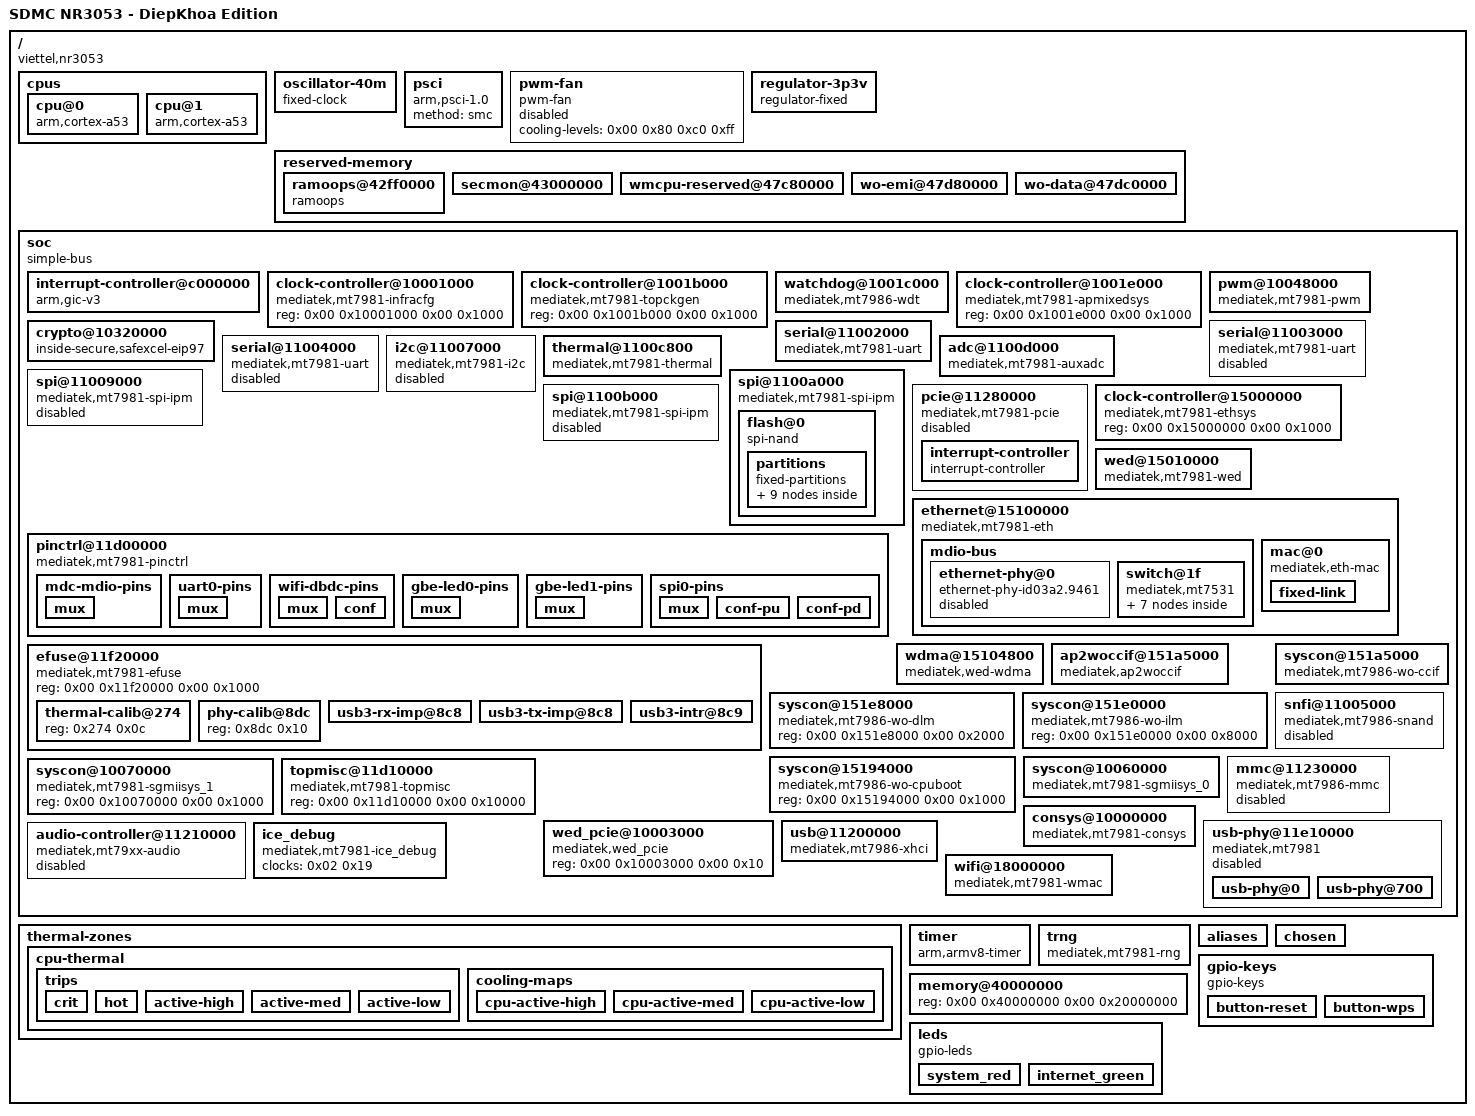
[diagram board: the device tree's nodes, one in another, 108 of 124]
/dts-v1/;

/ {
	compatible = "viettel,nr3053", "sdmc,nr3053", "mediatek,mt7981";
	interrupt-parent = <0x01>;
	#address-cells = <0x02>;
	#size-cells = <0x02>;
	model = "SDMC NR3053 - DiepKhoa Edition";

	cpus {
		#address-cells = <0x01>;
		#size-cells = <0x00>;

		cpu@0 {
			compatible = "arm,cortex-a53";
			reg = <0x00>;
			device_type = "cpu";
			enable-method = "psci";
		};

		cpu@1 {
			compatible = "arm,cortex-a53";
			reg = <0x01>;
			device_type = "cpu";
			enable-method = "psci";
		};
	};

	oscillator-40m {
		compatible = "fixed-clock";
		clock-frequency = <0x2625a00>;
		clock-output-names = "clkxtal";
		#clock-cells = <0x00>;
	};

	psci {
		compatible = "arm,psci-1.0";
		method = "smc";
	};

	pwm-fan {
		compatible = "pwm-fan";
		cooling-levels = <0x00 0x80 0xc0 0xff>;
		#cooling-cells = <0x02>;
		status = "disabled";
		phandle = <0x22>;
	};

	regulator-3p3v {
		compatible = "regulator-fixed";
		regulator-name = "fixed-3.3V";
		regulator-min-microvolt = <0x325aa0>;
		regulator-max-microvolt = <0x325aa0>;
		regulator-boot-on;
		regulator-always-on;
		phandle = <0x1d>;
	};

	reserved-memory {
		#address-cells = <0x02>;
		#size-cells = <0x02>;
		ranges;

		ramoops@42ff0000 {
			compatible = "ramoops";
			reg = <0x00 0x42ff0000 0x00 0x10000>;
			record-size = <0x1000>;
		};

		secmon@43000000 {
			reg = <0x00 0x43000000 0x00 0x30000>;
			no-map;
			phandle = <0x27>;
		};

		wmcpu-reserved@47c80000 {
			reg = <0x00 0x47c80000 0x00 0x100000>;
			no-map;
			phandle = <0x1b>;
		};

		wo-emi@47d80000 {
			reg = <0x00 0x47d80000 0x00 0x40000>;
			no-map;
			phandle = <0x0b>;
		};

		wo-data@47dc0000 {
			reg = <0x00 0x47dc0000 0x00 0x240000>;
			no-map;
			phandle = <0x0c>;
		};
	};

	soc {
		compatible = "simple-bus";
		ranges;
		#address-cells = <0x02>;
		#size-cells = <0x02>;

		interrupt-controller@c000000 {
			compatible = "arm,gic-v3";
			reg = <0x00 0xc000000 0x00 0x40000 0x00 0xc080000 0x00 0x200000>;
			interrupt-parent = <0x01>;
			interrupts = <0x01 0x09 0x04>;
			interrupt-controller;
			#interrupt-cells = <0x03>;
			phandle = <0x01>;
		};

		clock-controller@10001000 {
			compatible = "mediatek,mt7981-infracfg", "syscon";
			reg = <0x00 0x10001000 0x00 0x1000>;
			#clock-cells = <0x01>;
			phandle = <0x02>;
		};

		clock-controller@1001b000 {
			compatible = "mediatek,mt7981-topckgen", "syscon";
			reg = <0x00 0x1001b000 0x00 0x1000>;
			#clock-cells = <0x01>;
			phandle = <0x03>;
		};

		watchdog@1001c000 {
			compatible = "mediatek,mt7986-wdt";
			reg = <0x00 0x1001c000 0x00 0x1000>;
			interrupts = <0x00 0x6e 0x04>;
			#reset-cells = <0x01>;
			status = "okay";
			phandle = <0x1f>;
		};

		clock-controller@1001e000 {
			compatible = "mediatek,mt7981-apmixedsys", "syscon";
			reg = <0x00 0x1001e000 0x00 0x1000>;
			#clock-cells = <0x01>;
			phandle = <0x05>;
		};

		pwm@10048000 {
			compatible = "mediatek,mt7981-pwm";
			reg = <0x00 0x10048000 0x00 0x1000>;
			clocks = <0x02 0x0e 0x02 0x0d 0x02 0x0f 0x02 0x10 0x02 0x11>;
			clock-names = "top", "main", "pwm1", "pwm2", "pwm3";
			#pwm-cells = <0x02>;
			phandle = <0x28>;
		};

		crypto@10320000 {
			compatible = "inside-secure,safexcel-eip97";
			reg = <0x00 0x10320000 0x00 0x40000>;
			interrupts = <0x00 0x74 0x04 0x00 0x75 0x04 0x00 0x76 0x04 0x00 0x77 0x04>;
			interrupt-names = "ring0", "ring1", "ring2", "ring3";
			clocks = <0x03 0x42>;
			clock-names = "top_eip97_ck";
			assigned-clocks = <0x03 0x63>;
			assigned-clock-parents = <0x03 0x15>;
			phandle = <0x29>;
		};

		serial@11002000 {
			compatible = "mediatek,mt7981-uart", "mediatek,mt6577-uart";
			reg = <0x00 0x11002000 0x00 0x100>;
			interrupts = <0x00 0x7b 0x04>;
			interrupt-names = "uart", "wakeup";
			clocks = <0x02 0x01 0x02 0x1f>;
			clock-names = "baud", "bus";
			status = "okay";
			phandle = <0x2a>;
		};

		serial@11003000 {
			compatible = "mediatek,mt7981-uart", "mediatek,mt6577-uart";
			reg = <0x00 0x11003000 0x00 0x100>;
			interrupts = <0x00 0x7c 0x04>;
			interrupt-names = "uart", "wakeup";
			clocks = <0x02 0x02 0x02 0x20>;
			clock-names = "baud", "bus";
			status = "disabled";
			phandle = <0x2b>;
		};

		serial@11004000 {
			compatible = "mediatek,mt7981-uart", "mediatek,mt6577-uart";
			reg = <0x00 0x11004000 0x00 0x100>;
			interrupts = <0x00 0x7d 0x04>;
			interrupt-names = "uart", "wakeup";
			clocks = <0x02 0x03 0x02 0x21>;
			clock-names = "baud", "bus";
			status = "disabled";
			phandle = <0x2c>;
		};

		i2c@11007000 {
			compatible = "mediatek,mt7981-i2c";
			reg = <0x00 0x11007000 0x00 0x1000 0x00 0x10217080 0x00 0x80>;
			interrupts = <0x00 0x88 0x04>;
			clock-div = <0x01>;
			clocks = <0x02 0x1e 0x02 0x1a 0x02 0x33 0x02 0x34>;
			clock-names = "main", "dma", "arb", "pmic";
			#address-cells = <0x01>;
			#size-cells = <0x00>;
			status = "disabled";
			phandle = <0x2d>;
		};

		thermal@1100c800 {
			#thermal-sensor-cells = <0x01>;
			compatible = "mediatek,mt7981-thermal", "mediatek,mt7986-thermal";
			reg = <0x00 0x1100c800 0x00 0x800>;
			interrupts = <0x00 0x8a 0x04>;
			clocks = <0x02 0x1d 0x02 0x30>;
			clock-names = "therm", "auxadc";
			mediatek,auxadc = <0x04>;
			mediatek,apmixedsys = <0x05>;
			nvmem-cells = <0x06>;
			nvmem-cell-names = "calibration-data";
			phandle = <0x21>;
		};

		adc@1100d000 {
			compatible = "mediatek,mt7981-auxadc", "mediatek,mt7986-auxadc", "mediatek,mt7622-auxadc";
			reg = <0x00 0x1100d000 0x00 0x1000>;
			clocks = <0x02 0x30 0x02 0x31>;
			clock-names = "main", "32k";
			#io-channel-cells = <0x01>;
			phandle = <0x04>;
		};

		spi@11009000 {
			compatible = "mediatek,mt7981-spi-ipm", "mediatek,spi-ipm";
			reg = <0x00 0x11009000 0x00 0x1000>;
			interrupts = <0x00 0x8e 0x04>;
			clocks = <0x03 0x02 0x03 0x4e 0x02 0x22 0x02 0x23>;
			clock-names = "parent-clk", "sel-clk", "spi-clk", "hclk";
			#address-cells = <0x01>;
			#size-cells = <0x00>;
			status = "disabled";
			phandle = <0x2e>;
		};

		spi@1100a000 {
			compatible = "mediatek,mt7981-spi-ipm", "mediatek,spi-ipm";
			reg = <0x00 0x1100a000 0x00 0x1000>;
			interrupts = <0x00 0x8c 0x04>;
			clocks = <0x03 0x02 0x03 0x4e 0x02 0x27 0x02 0x29>;
			clock-names = "parent-clk", "sel-clk", "spi-clk", "hclk";
			#address-cells = <0x01>;
			#size-cells = <0x00>;
			status = "okay";
			pinctrl-names = "default";
			pinctrl-0 = <0x07>;
			phandle = <0x2f>;

			flash@0 {
				compatible = "spi-nand";
				reg = <0x00>;
				spi-max-frequency = <0x3197500>;
				spi-tx-bus-width = <0x04>;
				spi-rx-bus-width = <0x04>;
				mediatek,nmbm;
				mediatek,bmt-max-ratio = <0x01>;
				mediatek,bmt-max-reserved-blocks = <0x40>;
				phandle = <0x30>;

				partitions {
					compatible = "fixed-partitions";
					#address-cells = <0x01>;
					#size-cells = <0x01>;

					partition@0 {
						label = "bl2";
						reg = <0x00 0x100000>;
						read-only;
					};

					partition@100000 {
						label = "u-boot-env";
						reg = <0x100000 0x100000>;
					};

					partition@200000 {
						label = "Factory";
						reg = <0x200000 0x200000>;
						read-only;
						phandle = <0x20>;

						nvmem-layout {
							compatible = "fixed-layout";
							#address-cells = <0x01>;
							#size-cells = <0x01>;

							macaddr@4 {
								compatible = "mac-base";
								reg = <0x04 0x06>;
								#nvmem-cell-cells = <0x01>;
								phandle = <0x19>;
							};
						};
					};

					partition@400000 {
						label = "fip";
						reg = <0x400000 0x200000>;
						read-only;
					};

					partition@600000 {
						label = "ubi";
						reg = <0x600000 0xea00000>;
						compatible = "linux,ubi";

						volumes {
							ubi-volume-fit {
								volname = "fit";
								phandle = <0x26>;
							};
						};
					};
				};
			};
		};

		spi@1100b000 {
			compatible = "mediatek,mt7981-spi-ipm", "mediatek,spi-ipm";
			reg = <0x00 0x1100b000 0x00 0x1000>;
			interrupts = <0x00 0x8d 0x04>;
			clocks = <0x03 0x02 0x03 0x4e 0x02 0x28 0x02 0x2a>;
			clock-names = "parent-clk", "sel-clk", "spi-clk", "hclk";
			#address-cells = <0x01>;
			#size-cells = <0x00>;
			status = "disabled";
			phandle = <0x31>;
		};

		pcie@11280000 {
			compatible = "mediatek,mt7981-pcie", "mediatek,mt8192-pcie";
			device_type = "pci";
			reg = <0x00 0x11280000 0x00 0x4000>;
			reg-names = "pcie-mac";
			#address-cells = <0x03>;
			#size-cells = <0x02>;
			interrupts = <0x00 0xa8 0x04>;
			bus-range = <0x00 0xff>;
			ranges = <0x82000000 0x00 0x20000000 0x00 0x20000000 0x00 0x10000000>;
			status = "disabled";
			clocks = <0x02 0x39 0x02 0x3a 0x02 0x3b 0x02 0x3c>;
			phys = <0x08 0x02>;
			phy-names = "pcie-phy";
			#interrupt-cells = <0x01>;
			interrupt-map-mask = <0x00 0x00 0x00 0x07>;
			interrupt-map = <0x00 0x00 0x00 0x01 0x09 0x00 0x00 0x00 0x00 0x02 0x09 0x01 0x00 0x00 0x00 0x03 0x09 0x02 0x00 0x00 0x00 0x04 0x09 0x03>;
			phandle = <0x32>;

			interrupt-controller {
				interrupt-controller;
				#address-cells = <0x00>;
				#interrupt-cells = <0x01>;
				phandle = <0x09>;
			};
		};

		pinctrl@11d00000 {
			compatible = "mediatek,mt7981-pinctrl";
			reg = <0x00 0x11d00000 0x00 0x1000 0x00 0x11c00000 0x00 0x1000 0x00 0x11c10000 0x00 0x1000 0x00 0x11d20000 0x00 0x1000 0x00 0x11e00000 0x00 0x1000 0x00 0x11e20000 0x00 0x1000 0x00 0x11f00000 0x00 0x1000 0x00 0x11f10000 0x00 0x1000 0x00 0x1000b000 0x00 0x1000>;
			reg-names = "gpio", "iocfg_rt", "iocfg_rm", "iocfg_rb", "iocfg_lb", "iocfg_bl", "iocfg_tm", "iocfg_tl", "eint";
			interrupt-controller;
			interrupts = <0x00 0xe1 0x04>;
			interrupt-parent = <0x01>;
			gpio-ranges = <0x0a 0x00 0x00 0x38>;
			gpio-controller;
			#gpio-cells = <0x02>;
			#interrupt-cells = <0x02>;
			phandle = <0x0a>;

			mdc-mdio-pins {
				phandle = <0x33>;
				mux {
					function = "eth";
					groups = "smi_mdc_mdio";
				};
			};

			uart0-pins {
				phandle = <0x34>;
				mux {
					function = "uart";
					groups = "uart0";
				};
			};

			wifi-dbdc-pins {
				phandle = <0x1e>;
				mux {
					function = "eth";
					groups = "wf0_mode1";
				};
				conf {
					pins = "WF_HB1", "WF_HB2", "WF_HB3", "WF_HB4", "WF_HB0", "WF_HB0_B", "WF_HB5", "WF_HB6", "WF_HB7", "WF_HB8", "WF_HB9", "WF_HB10", "WF_TOP_CLK", "WF_TOP_DATA", "WF_XO_REQ", "WF_CBA_RESETB", "WF_DIG_RESETB";
					drive-strength = <0x04>;
				};
			};

			gbe-led0-pins {
				phandle = <0x17>;
				mux {
					function = "led";
					groups = "gbe_led0";
				};
			};

			gbe-led1-pins {
				phandle = <0x18>;
				mux {
					function = "led";
					groups = "gbe_led1";
				};
			};

			spi0-pins {
				phandle = <0x07>;
				mux {
					function = "spi";
					groups = "spi0", "spi0_wp_hold";
				};
				conf-pu {
					pins = "SPI0_CS", "SPI0_HOLD", "SPI0_WP";
					drive-strength = <0x08>;
					bias-pull-up = <0x67>;
				};
				conf-pd {
					pins = "SPI0_CLK", "SPI0_MOSI", "SPI0_MISO";
					drive-strength = <0x08>;
					bias-pull-down = <0x67>;
				};
			};
		};

		efuse@11f20000 {
			compatible = "mediatek,mt7981-efuse", "mediatek,efuse";
			reg = <0x00 0x11f20000 0x00 0x1000>;
			#address-cells = <0x01>;
			#size-cells = <0x01>;

			thermal-calib@274 {
				reg = <0x274 0x0c>;
				phandle = <0x06>;
			};

			phy-calib@8dc {
				reg = <0x8dc 0x10>;
				phandle = <0x16>;
			};

			usb3-rx-imp@8c8 {
				reg = <0x8c8 0x01>;
				bits = <0x00 0x05>;
				phandle = <0x35>;
			};

			usb3-tx-imp@8c8 {
				reg = <0x8c8 0x02>;
				bits = <0x05 0x05>;
				phandle = <0x36>;
			};

			usb3-intr@8c9 {
				reg = <0x8c9 0x01>;
				bits = <0x02 0x06>;
				phandle = <0x37>;
			};
		};

		clock-controller@15000000 {
			compatible = "mediatek,mt7981-ethsys", "syscon";
			reg = <0x00 0x15000000 0x00 0x1000>;
			#clock-cells = <0x01>;
			#reset-cells = <0x01>;
			phandle = <0x11>;
		};

		wed@15010000 {
			compatible = "mediatek,mt7981-wed", "mediatek,mt7986-wed", "syscon";
			reg = <0x00 0x15010000 0x00 0x1000>;
			interrupt-parent = <0x01>;
			interrupts = <0x00 0xcd 0x04>;
			memory-region = <0x0b 0x0c>;
			memory-region-names = "wo-emi", "wo-data";
			mediatek,wo-ccif = <0x0d>;
			mediatek,wo-ilm = <0x0e>;
			mediatek,wo-dlm = <0x0f>;
			mediatek,wo-cpuboot = <0x10>;
			phandle = <0x15>;
		};

		ethernet@15100000 {
			compatible = "mediatek,mt7981-eth";
			reg = <0x00 0x15100000 0x00 0x80000>;
			#address-cells = <0x01>;
			#size-cells = <0x00>;
			interrupts = <0x00 0xc4 0x04 0x00 0xc5 0x04 0x00 0xc6 0x04 0x00 0xc7 0x04>;
			clocks = <0x11 0x00 0x11 0x01 0x11 0x02 0x11 0x03 0x12 0x00 0x12 0x01 0x12 0x02 0x12 0x03 0x13 0x00 0x13 0x01 0x13 0x02 0x13 0x03 0x03 0x40 0x03 0x5d 0x03 0x5e>;
			clock-names = "fe", "gp2", "gp1", "wocpu0", "sgmii_tx250m", "sgmii_rx250m", "sgmii_cdr_ref", "sgmii_cdr_fb", "sgmii2_tx250m", "sgmii2_rx250m", "sgmii2_cdr_ref", "sgmii2_cdr_fb", "sgmii_ck", "netsys0", "netsys1";
			assigned-clocks = <0x03 0x60 0x03 0x61>;
			assigned-clock-parents = <0x03 0x1b 0x03 0x22>;
			mediatek,ethsys = <0x11>;
			mediatek,sgmiisys = <0x12 0x13>;
			mediatek,infracfg = <0x14>;
			mediatek,wed = <0x15>;
			status = "okay";
			phandle = <0x38>;

			mdio-bus {
				#address-cells = <0x01>;
				#size-cells = <0x00>;
				phandle = <0x39>;

				/* VO HIEU HOA PHY NOI BO DE XOA CONG LAN 4 AO */
				ethernet-phy@0 {
					reg = <0x00>;
					compatible = "ethernet-phy-id03a2.9461";
					phy-mode = "gmii";
					phy-is-integrated;
					status = "disabled";
				};

				switch@1f {
					compatible = "mediatek,mt7531";
					reg = <0x1f>;
					reset-gpios = <0x0a 0x27 0x00>;
					interrupt-controller;
					#interrupt-cells = <0x01>;
					interrupt-parent = <0x0a>;
					interrupts = <0x26 0x04>;
					phandle = <0x3d>;

					ports {
						#address-cells = <0x01>;
						#size-cells = <0x00>;

						port@0 {
							reg = <0x00>;
							label = "wan";
							nvmem-cells = <0x19 0x03>;
							nvmem-cell-names = "mac-address";
						};

						port@1 {
							reg = <0x01>;
							label = "lan1";
						};

						port@2 {
							reg = <0x02>;
							label = "lan2";
						};

						port@3 {
							reg = <0x03>;
							label = "lan3";
						};

						port@6 {
							reg = <0x06>;
							ethernet = <0x1a>;
							phy-mode = "2500base-x";

							fixed-link {
								speed = <0x9c4>;
								full-duplex;
								pause;
							};
						};
					};
				};
			};

			mac@0 {
				compatible = "mediatek,eth-mac";
				reg = <0x00>;
				phy-mode = "2500base-x";
				nvmem-cells = <0x19 0x02>;
				nvmem-cell-names = "mac-address";
				phandle = <0x1a>;

				fixed-link {
					speed = <0x9c4>;
					full-duplex;
					pause;
				};
			};
		};

		wdma@15104800 {
			compatible = "mediatek,wed-wdma";
			reg = <0x00 0x15104800 0x00 0x400 0x00 0x15104c00 0x00 0x400>;
			phandle = <0x3e>;
		};

		ap2woccif@151a5000 {
			compatible = "mediatek,ap2woccif";
			reg = <0x00 0x151a5000 0x00 0x1000 0x00 0x151ad000 0x00 0x1000>;
			interrupt-parent = <0x01>;
			interrupts = <0x00 0xd3 0x04 0x00 0xd4 0x04>;
			phandle = <0x3f>;
		};

		syscon@151e8000 {
			compatible = "mediatek,mt7986-wo-dlm", "syscon";
			reg = <0x00 0x151e8000 0x00 0x2000>;
			phandle = <0x0f>;
		};

		syscon@151e0000 {
			compatible = "mediatek,mt7986-wo-ilm", "syscon";
			reg = <0x00 0x151e0000 0x00 0x8000>;
			phandle = <0x0e>;
		};

		syscon@15194000 {
			compatible = "mediatek,mt7986-wo-cpuboot", "syscon";
			reg = <0x00 0x15194000 0x00 0x1000>;
			phandle = <0x10>;
		};

		syscon@151a5000 {
			compatible = "mediatek,mt7986-wo-ccif", "syscon";
			reg = <0x00 0x151a5000 0x00 0x1000>;
			interrupt-parent = <0x01>;
			interrupts = <0x00 0xd3 0x04>;
			phandle = <0x0d>;
		};

		syscon@10060000 {
			compatible = "mediatek,mt7981-sgmiisys_0", "mediatek,mt7986-sgmiisys_0", "syscon";
			reg = <0x00 0x10060000 0x00 0x1000>;
			mediatek,pnswap;
			#clock-cells = <0x01>;
			phandle = <0x12>;
		};

		syscon@10070000 {
			compatible = "mediatek,mt7981-sgmiisys_1", "mediatek,mt7986-sgmiisys_1", "syscon";
			reg = <0x00 0x10070000 0x00 0x1000>;
			#clock-cells = <0x01>;
			phandle = <0x13>;
		};

		topmisc@11d10000 {
			compatible = "mediatek,mt7981-topmisc", "syscon";
			reg = <0x00 0x11d10000 0x00 0x10000>;
			#clock-cells = <0x01>;
			phandle = <0x14>;
		};

		snfi@11005000 {
			compatible = "mediatek,mt7986-snand";
			reg = <0x00 0x11005000 0x00 0x1000 0x00 0x11006000 0x00 0x1000>;
			reg-names = "nfi", "ecc";
			interrupts = <0x00 0x79 0x04>;
			clocks = <0x02 0x25 0x02 0x24 0x02 0x26>;
			clock-names = "pad_clk", "nfi_clk", "nfi_hclk";
			assigned-clocks = <0x03 0x4d 0x03 0x4c>;
			assigned-clock-parents = <0x03 0x06 0x03 0x06>;
			#address-cells = <0x01>;
			#size-cells = <0x00>;
			status = "disabled";
			phandle = <0x40>;
		};

		mmc@11230000 {
			compatible = "mediatek,mt7986-mmc", "mediatek,mt7981-mmc";
			reg = <0x00 0x11230000 0x00 0x1000 0x00 0x11c20000 0x00 0x1000>;
			interrupts = <0x00 0x8f 0x04>;
			clocks = <0x02 0x2c 0x02 0x2d 0x02 0x2f 0x02 0x2e>;
			assigned-clocks = <0x03 0x54 0x03 0x55>;
			assigned-clock-parents = <0x03 0x02 0x03 0x1c>;
			clock-names = "source", "hclk", "axi_cg", "ahb_cg";
			status = "disabled";
			phandle = <0x41>;
		};

		wed_pcie@10003000 {
			compatible = "mediatek,wed_pcie";
			reg = <0x00 0x10003000 0x00 0x10>;
			phandle = <0x42>;
		};

		consys@10000000 {
			compatible = "mediatek,mt7981-consys";
			reg = <0x00 0x10000000 0x00 0x8600000>;
			memory-region = <0x1b>;
			phandle = <0x43>;
		};

		usb@11200000 {
			compatible = "mediatek,mt7986-xhci", "mediatek,mtk-xhci";
			reg = <0x00 0x11200000 0x00 0x2e00 0x00 0x11203e00 0x00 0x100>;
			reg-names = "mac", "ippc";
			interrupts = <0x00 0xad 0x04>;
			clocks = <0x02 0x37 0x02 0x38 0x02 0x35 0x02 0x36 0x03 0x6b>;
			clock-names = "sys_ck", "ref_ck", "mcu_ck", "dma_ck", "xhci_ck";
			phys = <0x1c 0x03 0x08 0x04>;
			vusb33-supply = <0x1d>;
			status = "okay";
			phandle = <0x44>;
		};

		usb-phy@11e10000 {
			compatible = "mediatek,mt7981", "mediatek,generic-tphy-v2";
			#address-cells = <0x01>;
			#size-cells = <0x01>;
			ranges = <0x00 0x00 0x11e10000 0x1700>;
			status = "disabled";
			phandle = <0x45>;

			usb-phy@0 {
				reg = <0x00 0x700>;
				clocks = <0x03 0x6c>;
				clock-names = "ref";
				#phy-cells = <0x01>;
				phandle = <0x1c>;
			};

			usb-phy@700 {
				reg = <0x700 0x900>;
				clocks = <0x03 0x64>;
				clock-names = "ref";
				#phy-cells = <0x01>;
				mediatek,syscon-type = <0x14 0x218 0x00>;
				status = "okay";
				phandle = <0x08>;
			};
		};

		audio-controller@11210000 {
			compatible = "mediatek,mt79xx-audio";
			reg = <0x00 0x11210000 0x00 0x9000>;
			interrupts = <0x00 0x6a 0x04>;
			clocks = <0x02 0x13 0x02 0x14 0x02 0x15 0x02 0x16 0x02 0x17 0x03 0x65>;
			clock-names = "aud_bus_ck", "aud_26m_ck", "aud_l_ck", "aud_aud_ck", "aud_eg2_ck", "aud_sel";
			assigned-clocks = <0x03 0x65 0x03 0x66 0x03 0x67 0x03 0x68>;
			assigned-clock-parents = <0x03 0x10 0x03 0x12 0x03 0x10 0x03 0x12>;
			status = "disabled";
			phandle = <0x46>;
		};

		ice_debug {
			compatible = "mediatek,mt7981-ice_debug", "mediatek,mt2701-ice_debug";
			clocks = <0x02 0x19>;
			clock-names = "ice_dbg";
			phandle = <0x47>;
		};

		wifi@18000000 {
			compatible = "mediatek,mt7981-wmac";
			pinctrl-0 = <0x1e>;
			pinctrl-names = "dbdc";
			reg = <0x00 0x18000000 0x00 0x1000000 0x00 0x10003000 0x00 0x1000 0x00 0x11d10000 0x00 0x1000>;
			interrupts = <0x00 0xd5 0x04 0x00 0xd6 0x04 0x00 0xd7 0x04 0x00 0xd8 0x04>;
			clocks = <0x03 0x5f 0x03 0x5c>;
			clock-names = "mcu", "ap2conn";
			resets = <0x1f 0x17>;
			reset-names = "consys";
			memory-region = <0x1b>;
			status = "okay";
			mediatek,mtd-eeprom = <0x20 0x00>;
			phandle = <0x48>;
		};
	};

	thermal-zones {

		cpu-thermal {
			polling-delay-passive = <0x3e8>;
			polling-delay = <0x3e8>;
			thermal-sensors = <0x21 0x00>;
			phandle = <0x49>;

			trips {

				crit {
					temperature = <0x1e848>;
					hysteresis = <0x7d0>;
					type = "critical";
					phandle = <0x4a>;
				};

				hot {
					temperature = <0x1d4c0>;
					hysteresis = <0x7d0>;
					type = "hot";
					phandle = <0x4b>;
				};

				active-high {
					temperature = <0x1c138>;
					hysteresis = <0x7d0>;
					type = "active";
					phandle = <0x23>;
				};

				active-med {
					temperature = <0x14c08>;
					hysteresis = <0x7d0>;
					type = "active";
					phandle = <0x24>;
				};

				active-low {
					temperature = <0xea60>;
					hysteresis = <0x7d0>;
					type = "active";
					phandle = <0x25>;
				};
			};

			cooling-maps {

				cpu-active-high {
					cooling-device = <0x22 0x03 0x03>;
					trip = <0x23>;
				};

				cpu-active-med {
					cooling-device = <0x22 0x02 0x02>;
					trip = <0x24>;
				};

				cpu-active-low {
					cooling-device = <0x22 0x01 0x01>;
					trip = <0x25>;
				};
			};
		};
	};

	timer {
		compatible = "arm,armv8-timer";
		interrupt-parent = <0x01>;
		interrupts = <0x01 0x0d 0x08 0x01 0x0e 0x08 0x01 0x0b 0x08 0x01 0x0a 0x08>;
	};

	trng {
		compatible = "mediatek,mt7981-rng";
	};

	aliases {
		serial0 = "/soc/serial@11002000";
		label-mac-device = "/soc/ethernet@15100000/mac@0";
		led-boot = "/leds/system_red";
		led-failsafe = "/leds/system_red";
		led-running = "/leds/internet_green";
		led-upgrade = "/leds/system_red";
	};

	chosen {
		bootargs = "console=ttyS0,115200n1 loglevel=8 earlycon=uart8250,mmio32,0x11002000";
		u-boot,bootconf = "config-1#mt7981b-sdmc-nr3053";
		u-boot,version = "2025.10-ImmortalWrt-r37678-ff1ea58da2";
		rootdisk = <0x26>;
		stdout-path = "serial0:115200n8";
	};

	memory@40000000 {
		device_type = "memory";
		reg = <0x00 0x40000000 0x00 0x20000000>;
	};

	gpio-keys {
		compatible = "gpio-keys";

		button-reset {
			label = "reset";
			linux,code = <0x198>;
			gpios = <0x0a 0x01 0x01>;
		};

		button-wps {
			label = "wps";
			linux,code = <0x211>;
			gpios = <0x0a 0x00 0x01>;
		};
	};

	leds {
		compatible = "gpio-leds";

		system_red {
			function = "status";
			color = <0x01>;
			gpios = <0x0a 0x06 0x01>;
			default-state = "on";
			phandle = <0x4c>;
		};

		internet_green {
			function = "wan";
			color = <0x02>;
			gpios = <0x0a 0x04 0x01>;
			phandle = <0x4d>;
		};
	};

	__symbols__ {
		fan = "/pwm-fan";
		reg_3p3v = "/regulator-3p3v";
		secmon_reserved = "/reserved-memory/secmon@43000000";
		wmcpu_emi = "/reserved-memory/wmcpu-reserved@47c80000";
		wo_emi0 = "/reserved-memory/wo-emi@47d80000";
		wo_data = "/reserved-memory/wo-data@47dc0000";
		gic = "/soc/interrupt-controller@c000000";
		infracfg = "/soc/clock-controller@10001000";
		topckgen = "/soc/clock-controller@1001b000";
		watchdog = "/soc/watchdog@1001c000";
		apmixedsys = "/soc/clock-controller@1001e000";
		pwm = "/soc/pwm@10048000";
		crypto = "/soc/crypto@10320000";
		uart0 = "/soc/serial@11002000";
		uart1 = "/soc/serial@11003000";
		uart2 = "/soc/serial@11004000";
		i2c0 = "/soc/i2c@11007000";
		thermal = "/soc/thermal@1100c800";
		auxadc = "/soc/adc@1100d000";
		spi2 = "/soc/spi@11009000";
		spi0 = "/soc/spi@1100a000";
		spi_nand = "/soc/spi@1100a000/flash@0";
		factory = "/soc/spi@1100a000/flash@0/partitions/partition@200000";
		macaddr_factory_4 = "/soc/spi@1100a000/flash@0/partitions/partition@200000/nvmem-layout/macaddr@4";
		ubi_rootdisk = "/soc/spi@1100a000/flash@0/partitions/partition@600000/volumes/ubi-volume-fit";
		spi1 = "/soc/spi@1100b000";
		pcie = "/soc/pcie@11280000";
		pcie_intc = "/soc/pcie@11280000/interrupt-controller";
		pio = "/soc/pinctrl@11d00000";
		mdio_pins = "/soc/pinctrl@11d00000/mdc-mdio-pins";
		uart0_pins = "/soc/pinctrl@11d00000/uart0-pins";
		wifi_dbdc_pins = "/soc/pinctrl@11d00000/wifi-dbdc-pins";
		gbe_led0_pins = "/soc/pinctrl@11d00000/gbe-led0-pins";
		gbe_led1_pins = "/soc/pinctrl@11d00000/gbe-led1-pins";
		spi0_flash_pins = "/soc/pinctrl@11d00000/spi0-pins";
		thermal_calibration = "/soc/efuse@11f20000/thermal-calib@274";
		phy_calibration = "/soc/efuse@11f20000/phy-calib@8dc";
		comb_rx_imp_p0 = "/soc/efuse@11f20000/usb3-rx-imp@8c8";
		comb_tx_imp_p0 = "/soc/efuse@11f20000/usb3-tx-imp@8c8";
		comb_intr_p0 = "/soc/efuse@11f20000/usb3-intr@8c9";
		ethsys = "/soc/clock-controller@15000000";
		wed = "/soc/wed@15010000";
		eth = "/soc/ethernet@15100000";
		mdio_bus = "/soc/ethernet@15100000/mdio-bus";
		switch = "/soc/ethernet@15100000/mdio-bus/switch@1f";
		gmac0 = "/soc/ethernet@15100000/mac@0";
		wdma = "/soc/wdma@15104800";
		ap2woccif = "/soc/ap2woccif@151a5000";
		wo_dlm0 = "/soc/syscon@151e8000";
		wo_ilm0 = "/soc/syscon@151e0000";
		wo_cpuboot = "/soc/syscon@15194000";
		wo_ccif0 = "/soc/syscon@151a5000";
		sgmiisys0 = "/soc/syscon@10060000";
		sgmiisys1 = "/soc/syscon@10070000";
		topmisc = "/soc/topmisc@11d10000";
		snand = "/soc/snfi@11005000";
		mmc0 = "/soc/mmc@11230000";
		wed_pcie = "/soc/wed_pcie@10003000";
		consys = "/soc/consys@10000000";
		xhci = "/soc/usb@11200000";
		usb_phy = "/soc/usb-phy@11e10000";
		u2port0 = "/soc/usb-phy@11e10000/usb-phy@0";
		u3port0 = "/soc/usb-phy@11e10000/usb-phy@700";
		afe = "/soc/audio-controller@11210000";
		ice = "/soc/ice_debug";
		wifi = "/soc/wifi@18000000";
		cpu_thermal = "/thermal-zones/cpu-thermal";
		cpu_trip_crit = "/thermal-zones/cpu-thermal/trips/crit";
		cpu_trip_hot = "/thermal-zones/cpu-thermal/trips/hot";
		cpu_trip_active_high = "/thermal-zones/cpu-thermal/trips/active-high";
		cpu_trip_active_med = "/thermal-zones/cpu-thermal/trips/active-med";
		cpu_trip_active_low = "/thermal-zones/cpu-thermal/trips/active-low";
		led_system_red = "/leds/system_red";
		led_internet_green = "/leds/internet_green";
	};
};
